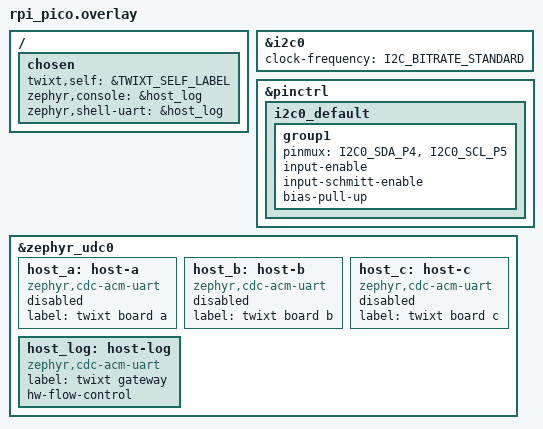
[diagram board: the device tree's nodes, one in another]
/*
 * Copyright (c) 2026 Christoph Jans <jans.christoph@gmail.com>
 *
 * SPDX-License-Identifier: Apache-2.0
 */

/* The gateway on a Raspberry Pi Pico: the bus on I2C0, SDA GP4 (pin 6) and SCL
 * GP5 (pin 7); the boards are USB CDC-ACM ports on the laptop, /dev/ttyACM*,
 * and so is the gateway's own shell and log. The Pico is only the gateway
 * (-DMCU=gw).
 */

/ {
	chosen {
		twixt,self = &TWIXT_SELF_LABEL;
		zephyr,console = &host_log;
		zephyr,shell-uart = &host_log;
	};
};

&i2c0 {
	clock-frequency = <I2C_BITRATE_STANDARD>;

#include "../twixt_mcus.dtsi"
};

&pinctrl {
	i2c0_default: i2c0_default {
		group1 {
			pinmux = <I2C0_SDA_P4>, <I2C0_SCL_P5>;
			input-enable;
			input-schmitt-enable;
			bias-pull-up; /* weak; the bus needs its own pull-ups */
		};
	};
};

/* The gateway's ports to the laptop (gateway.overlay enables them) */
&zephyr_udc0 {
	host_a: host-a {
		compatible = "zephyr,cdc-acm-uart";
		label = "twixt board a";
		status = "disabled";
	};

	host_b: host-b {
		compatible = "zephyr,cdc-acm-uart";
		label = "twixt board b";
		status = "disabled";
	};

	host_c: host-c {
		compatible = "zephyr,cdc-acm-uart";
		label = "twixt board c";
		status = "disabled";
	};

	/* Last, so the boards keep their interfaces */
	host_log: host-log {
		compatible = "zephyr,cdc-acm-uart";
		label = "twixt gateway";
		hw-flow-control;
	};
};
